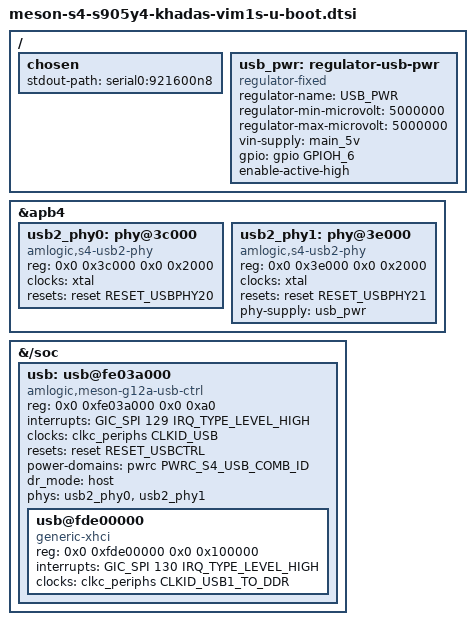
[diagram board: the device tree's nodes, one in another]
#include <dt-bindings/power/meson-s4-power.h>

/ {
	chosen {
		stdout-path = "serial0:921600n8";
	};

	usb_pwr: regulator-usb-pwr {
		compatible = "regulator-fixed";
		regulator-name = "USB_PWR";
		regulator-min-microvolt = <5000000>;
		regulator-max-microvolt = <5000000>;
		vin-supply = <&main_5v>;
		gpio = <&gpio GPIOH_6 GPIO_ACTIVE_HIGH>;
		enable-active-high;
	};
};

&apb4 {
	usb2_phy0: phy@3c000 {
		compatible = "amlogic,s4-usb2-phy";
		reg = <0x0 0x3c000 0x0 0x2000>;
		clocks = <&xtal>;
		clock-names = "xtal";
		resets = <&reset RESET_USBPHY20>;
		reset-names = "phy";
		#phy-cells = <0>;
	};

	usb2_phy1: phy@3e000 {
		compatible = "amlogic,s4-usb2-phy";
		reg = <0x0 0x3e000 0x0 0x2000>;
		clocks = <&xtal>;
		clock-names = "xtal";
		resets = <&reset RESET_USBPHY21>;
		reset-names = "phy";
		#phy-cells = <0>;
		phy-supply = <&usb_pwr>;
	};
};

&{/soc} {
	usb: usb@fe03a000 {
		compatible = "amlogic,meson-g12a-usb-ctrl";
		reg = <0x0 0xfe03a000 0x0 0xa0>;
		interrupts = <GIC_SPI 129 IRQ_TYPE_LEVEL_HIGH>;
		#address-cells = <2>;
		#size-cells = <2>;
		ranges;
		clocks = <&clkc_periphs CLKID_USB>;
		resets = <&reset RESET_USBCTRL>;
		power-domains = <&pwrc PWRC_S4_USB_COMB_ID>;
		dr_mode = "host";
		phys = <&usb2_phy0>, <&usb2_phy1>;
		phy-names = "usb2-phy0", "usb2-phy1";

		usb@fde00000 {
			compatible = "generic-xhci";
			reg = <0x0 0xfde00000 0x0 0x100000>;
			interrupts = <GIC_SPI 130 IRQ_TYPE_LEVEL_HIGH>;
			clocks = <&clkc_periphs CLKID_USB1_TO_DDR>;
		};
	};
};
